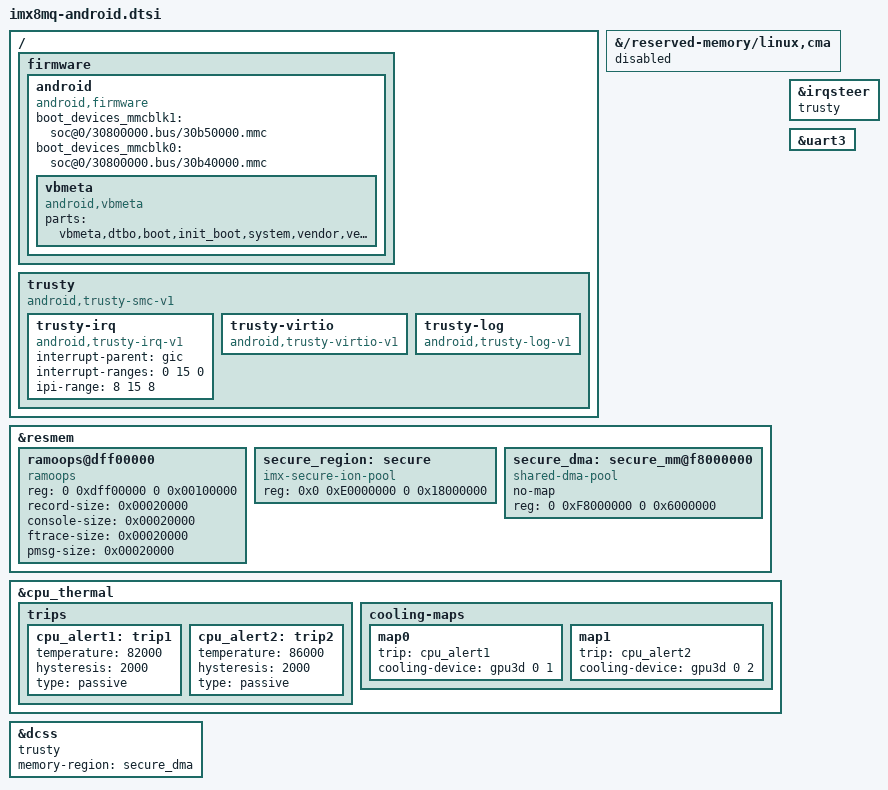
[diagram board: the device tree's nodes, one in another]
// SPDX-License-Identifier: (GPL-2.0+ OR MIT)
/*
 * Copyright 2022 NXP
 */

/ {
	firmware {
		android {
			compatible = "android,firmware";
			/* sd card node which used if androidboot.boot_device_root=mmcblk1 */
			boot_devices_mmcblk1 = "soc@0/30800000.bus/30b50000.mmc";
			/* emmc node which used if androidboot.boot_device_root=mmcblk0 */
			boot_devices_mmcblk0 = "soc@0/30800000.bus/30b40000.mmc";
			vbmeta {
				/*we need use FirstStageMountVBootV2 if we enable avb*/
				compatible = "android,vbmeta";
				/*parts means the partition witch can be mount in first stage*/
				parts = "vbmeta,dtbo,boot,init_boot,system,vendor,vendor_dlkm,product";
			};
		};
	};

	trusty {
		compatible = "android,trusty-smc-v1";
		ranges;
		#address-cells = <2>;
		#size-cells = <2>;
		trusty-irq {
			compatible = "android,trusty-irq-v1";
			interrupt-parent = <&gic>;
			interrupt-ranges = < 0 15 0>;
			ipi-range = <8 15 8>;
		};
		trusty-virtio {
			compatible = "android,trusty-virtio-v1";
		};
		trusty-log {
			compatible = "android,trusty-log-v1";
		};
	};
};

&{/reserved-memory/linux,cma} {
	status = "disabled";
};

&resmem {
	ramoops@dff00000 {
		compatible = "ramoops";
		reg = <0 0xdff00000 0 0x00100000>;
		record-size     = <0x00020000>;
		console-size    = <0x00020000>;
		ftrace-size     = <0x00020000>;
		pmsg-size       = <0x00020000>;
	};

	/* secure heap for secure video playback (up to 4K) */
	secure_region: secure {
		 compatible = "imx-secure-ion-pool";
		 reg = <0x0 0xE0000000 0 0x18000000>;
	};
	secure_dma: secure_mm@f8000000 {
		compatible = "shared-dma-pool";
		no-map;
		reg = <0 0xF8000000 0 0x6000000>;
	};
};

&cpu_thermal {
	trips {
		cpu_alert1: trip1 {
			temperature = <82000>;
			hysteresis = <2000>;
			type = "passive";
		};
		cpu_alert2: trip2 {
			temperature = <86000>;
			hysteresis = <2000>;
			type = "passive";
		};
	};

	cooling-maps {
		map0 {
			trip = <&cpu_alert1>;
			cooling-device =
				<&gpu3d 0 1>;
		};
		map1 {
			trip = <&cpu_alert2>;
			cooling-device =
				<&gpu3d 0 2>;
		};
	};
};

&dcss {
	trusty;
	memory-region = <&secure_dma>;
};

&irqsteer {
	trusty;
};

&uart3 {
       /delete-node/ bluetooth;
};
